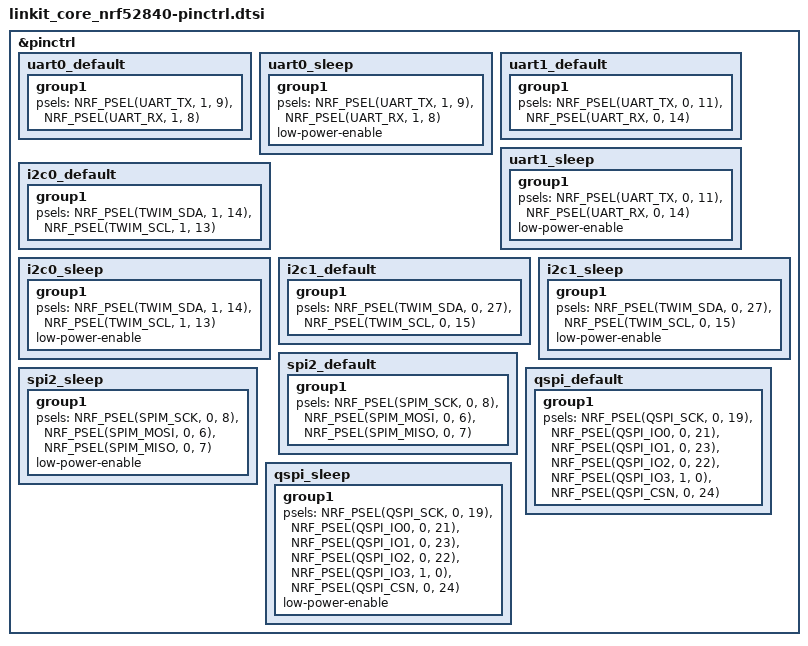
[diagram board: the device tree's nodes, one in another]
/*
 * Copyright (c) 2022 Nordic Semiconductor
 * SPDX-License-Identifier: Apache-2.0
 */
 &pinctrl {
    uart0_default: uart0_default {
        group1 {
            psels = <NRF_PSEL(UART_TX, 1, 9)>,
                    <NRF_PSEL(UART_RX, 1, 8)>;
        };
    };

    uart0_sleep: uart0_sleep {
        group1 {
            psels = <NRF_PSEL(UART_TX, 1, 9)>,
                    <NRF_PSEL(UART_RX, 1, 8)>;
            low-power-enable;
        };
    };

    uart1_default: uart1_default {
        group1 {
            psels = <NRF_PSEL(UART_TX, 0, 11)>,
                    <NRF_PSEL(UART_RX, 0, 14)>;
        };
    };

    uart1_sleep: uart1_sleep {
        group1 {
            psels = <NRF_PSEL(UART_TX, 0, 11)>,
                    <NRF_PSEL(UART_RX, 0, 14)>;
            low-power-enable;
        };
    };

    i2c0_default: i2c0_default {
        group1 {
            psels = <NRF_PSEL(TWIM_SDA, 1, 14)>,
                    <NRF_PSEL(TWIM_SCL, 1, 13)>;
        };
    };

    i2c0_sleep: i2c0_sleep {
        group1 {
            psels = <NRF_PSEL(TWIM_SDA, 1, 14)>,
                    <NRF_PSEL(TWIM_SCL, 1, 13)>;
            low-power-enable;
        };
    };

    i2c1_default: i2c1_default {
        group1 {
            psels = <NRF_PSEL(TWIM_SDA, 0, 27)>,
                    <NRF_PSEL(TWIM_SCL, 0, 15)>;
        };
    };

    i2c1_sleep: i2c1_sleep {
        group1 {
            psels = <NRF_PSEL(TWIM_SDA, 0, 27)>,
                    <NRF_PSEL(TWIM_SCL, 0, 15)>;
            low-power-enable;
        };
    };

    spi2_default: spi2_default {
        group1 {
            psels = <NRF_PSEL(SPIM_SCK, 0, 8)>,
                    <NRF_PSEL(SPIM_MOSI, 0, 6)>,
                    <NRF_PSEL(SPIM_MISO, 0, 7)>;
        };
    };

    spi2_sleep: spi2_sleep {
        group1 {
            psels = <NRF_PSEL(SPIM_SCK, 0, 8)>,
                    <NRF_PSEL(SPIM_MOSI, 0, 6)>,
                    <NRF_PSEL(SPIM_MISO, 0, 7)>;
            low-power-enable;
        };
    };

    qspi_default: qspi_default {
        group1 {
            psels = <NRF_PSEL(QSPI_SCK, 0, 19)>,
                    <NRF_PSEL(QSPI_IO0, 0, 21)>,
                    <NRF_PSEL(QSPI_IO1, 0, 23)>,
                    <NRF_PSEL(QSPI_IO2, 0, 22)>,
                    <NRF_PSEL(QSPI_IO3, 1, 0)>,
                    <NRF_PSEL(QSPI_CSN, 0, 24)>;
        };
    };

    qspi_sleep: qspi_sleep {
        group1 {
            psels = <NRF_PSEL(QSPI_SCK, 0, 19)>,
                    <NRF_PSEL(QSPI_IO0, 0, 21)>,
                    <NRF_PSEL(QSPI_IO1, 0, 23)>,
                    <NRF_PSEL(QSPI_IO2, 0, 22)>,
                    <NRF_PSEL(QSPI_IO3, 1, 0)>,
                    <NRF_PSEL(QSPI_CSN, 0, 24)>;
            low-power-enable;
        };
    };
};
